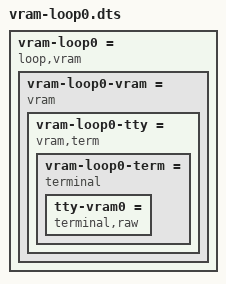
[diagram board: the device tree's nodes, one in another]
/**
 * Copyright (C) 2022 Jan Nowotsch
 * Author Jan Nowotsch	<jan.nowotsch@gmail.com>
 *
 * Released under the terms of the GNU GPL v2.0
 */



#include <term.dts>
#include <vram.dts>


vram-loop0 = {
	compatible = "loop,vram";

	vram-loop0-vram = {
		compatible = "vram";

		vram_cfg_t(
			32,		// height
			64,		// width
			0x10,	// contrast
			0x00,	// flags
		 	100		// refresh_ms
		)

		vram-loop0-tty = {
			compatible = "vram,term";

			vram-loop0-term = {
				compatible = "terminal";

				term_cfg_t(
					0x0,	// iflags (none)
					0x0,	// oflags (none)
					0x2,	// lflags (TLFL_CANON)
					2		// tabs
				)

				tty-vram0 = {
					compatible = "terminal,raw";
				};
			};
		};
	};
};
